# STM32L0x1 register map
File version: 1.6
CPU: CM0+ r0p0, little endian, MPU, no FPU, 2 interrupt priority bits
Registers are 32-bit, read-write, reset 0x0 unless marked. A register's access mark holds for its fields unless they carry their own. Offsets are from the block's base; [hi:lo] are bit positions.

## PWR — Power control
Base 0x40007000
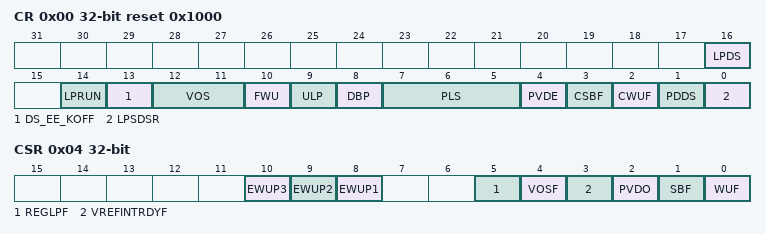
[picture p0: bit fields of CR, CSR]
0x00 CR reset 0x1000 — power control register
  [16] LPDS — Regulator in Low-power deepsleep mode This bit allows switching the regulator to low-power mode when the CPU enters Stop mode. Its behavior depends on LPSDSR bit
    0=MAIN_MODE (Voltage regulator in Main mode during Deepsleep mode (Stop mode)); 1=LOW_POWER_MODE (Voltage regulator switches to low-power mode when the CPU enters Deepsleep mode (Stop mode))
  [14] LPRUN — Low power run mode
    0=MAIN_MODE (Voltage regulator in Main mode in Low-power run mode); 1=LOW_POWER_MODE (Voltage regulator in low-power mode in Low-power run mode)
  [13] DS_EE_KOFF — Deep sleep mode with Flash memory kept off
    0=NVMWakeUp (NVM woken up when exiting from Deepsleep mode even if the bit RUN_PD is set); 1=NVMSleep (NVM not woken up when exiting from low-power mode (if the bit RUN_PD is set))
  [12:11] VOS — Voltage scaling range selection
    1=V1_8 (1.8 V (range 1)); 2=V1_5 (1.5 V (range 2)); 3=V1_2 (1.2 V (range 3))
  [10] FWU — Fast wakeup
    0=Disabled (Low-power modes exit occurs only when VREFINT is ready); 1=Enabled (VREFINT start up time is ignored when exiting low-power modes)
  [9] ULP — Ultra-low-power mode
    0=Enabled (VREFINT is on in low-power mode); 1=Disabled (VREFINT is off in low-power mode)
  [8] DBP — Disable backup domain write protection
    0=Disabled (Access to RTC, RTC Backup and RCC CSR registers disabled); 1=Enabled (Access to RTC, RTC Backup and RCC CSR registers enabled)
  [7:5] PLS — PVD level selection
    0=V1_9 (1.9 V); 1=V2_1 (2.1 V); 2=V2_3 (2.3 V); 3=V2_5 (2.5 V); 4=V2_7 (2.7 V); 5=V2_9 (2.9 V); 6=V3_1 (3.1 V); 7=External input analog voltage (Compare internally to VREFINT)
  [4] PVDE — Power voltage detector enable
    0=Disabled (PVD Disabled); 1=Enabled (PVD Enabled)
  [3] CSBF — Clear standby flag
    on write: 1=Clear the SBF Standby flag
  [2] CWUF — Clear wakeup flag
    on write: 1=Clear the WUF Wakeup flag after 2 system clock cycles
  [1] PDDS — Power down deepsleep
    0=STOP_MODE (Enter Stop mode when the CPU enters deepsleep); 1=STANDBY_MODE (Enter Standby mode when the CPU enters deepsleep)
  [0] LPSDSR — Low-power deepsleep/Sleep/Low-power run
    0=MAIN_MODE (Voltage regulator on during Deepsleep/Sleep/Low-power run mode); 1=LOW_POWER_MODE (Voltage regulator in low-power mode during Deepsleep/Sleep/Low-power run mode)
0x04 CSR access per field — power control/status register
  [10] EWUP3 rw — Enable WKUP pin 3
    0=Disabled (WKUP pin 3 is used for general purpose I/Os. An event on the WKUP pin 3 does not wakeup the device from Standby mode); 1=Enabled (WKUP pin 3 is used for wakeup from Standby mode and forced in input pull down configuration (rising edge on WKUP pin 3wakes-up the system from Standby mode))
  [9] EWUP2 rw — Enable WKUP pin 2
    0=Disabled (WKUP pin 2 is used for general purpose I/Os. An event on the WKUP pin 2 does not wakeup the device from Standby mode); 1=Enabled (WKUP pin 2 is used for wakeup from Standby mode and forced in input pull down configuration (rising edge on WKUP pin 2 wakes-up the system from Standby mode))
  [8] EWUP1 rw — Enable WKUP pin 1
    0=Disabled (WKUP pin 1 is used for general purpose I/Os. An event on the WKUP pin 1 does not wakeup the device from Standby mode); 1=Enabled (WKUP pin 1 is used for wakeup from Standby mode and forced in input pull down configuration (rising edge on WKUP pin 1 wakes-up the system from Standby mode))
  [5] REGLPF ro — Regulator LP flag
    0=Ready (Regulator is ready in Main mode); 1=NotReady (Regulator voltage is in low-power mode)
  [4] VOSF ro — Voltage Scaling select flag
    0=Ready (Regulator is ready in the selected voltage range); 1=NotReady (Regulator voltage output is changing to the required VOS level)
  [3] VREFINTRDYF ro — Internal voltage reference (VREFINT) ready flag This bit indicates the state of the internal voltage reference, VREFINT.
    0=NotReady (VREFINT is OFF); 1=Ready (VREFINT is ready)
  [2] PVDO ro — PVD output
    0=AboveThreshold (VDD is higher than the PVD threshold selected with the PLS[2:0] bits); 1=BelowThreshold (VDD is lower than the PVD threshold selected with the PLS[2:0] bits)
  [1] SBF ro — Standby flag
    0=NoStandbyEvent (Device has not been in Standby mode); 1=StandbyEvent (Device has been in Standby mode)
  [0] WUF ro — Wakeup flag
    0=No wakeup event occurred; 1=WakeupEvent (A wakeup event was received from the WKUP pin or from the RTC alarm (Alarm A or Alarm B), RTC Tamper event, RTC TimeStamp event or RTC Wakeup))
